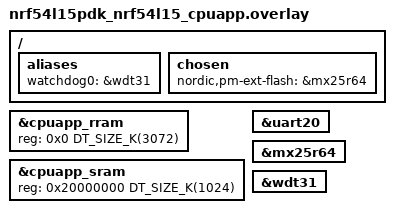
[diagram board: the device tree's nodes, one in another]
/*
 * Copyright (c) 2024 Nordic Semiconductor ASA
 *
 * SPDX-License-Identifier: LicenseRef-Nordic-5-Clause
 */

/ {
	aliases {
		// Use watchdog wdt31 as the application watchdog
		watchdog0 = &wdt31;
	};

	chosen {
		nordic,pm-ext-flash = &mx25r64;
	};
};

// Extend RRAM size to 3MB
&cpuapp_rram {
	reg = <0x0 DT_SIZE_K(3072)>;
};

// Extend RAM to 1 MB
&cpuapp_sram {
	reg = <0x20000000 DT_SIZE_K(1024)>;
	ranges = <0x0 0x20000000  0x100000>;
};

// TODO: re-enable HWFC once it's fixed
&uart20 {
	/delete-property/ hw-flow-control;
};

&mx25r64 {
	status = "okay";
};

&wdt31 {
	status = "okay";
};
